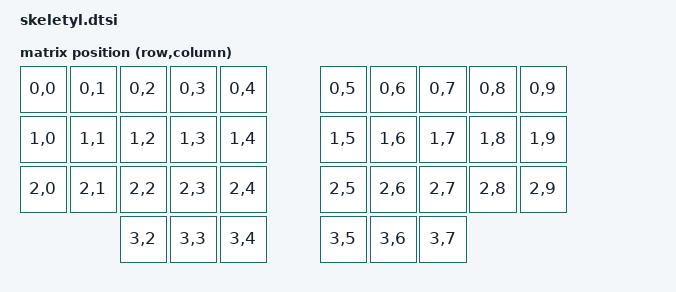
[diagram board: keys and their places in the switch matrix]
// This file was generated from a template. Edit it to match your keyboard.
// See https://zmk.dev/docs/development/hardware-integration/new-shield for more
// instructions.

#include <dt-bindings/zmk/matrix_transform.h>

#include "skeletyl-layouts.dtsi"

/ {
    chosen {
        zmk,kscan = &kscan
        zmk,physical-layout = &default_layout;
    };

    kscan: kscan {
        // Set this to "col2row" or "row2col" to match the hardware. If using
        // "row2col", change the col-gpios in the _left.overlay and _right.overlay
        // files to (GPIO_ACTIVE_HIGH | GPIO_PULL_DOWN) and the row-gpios here to
        // GPIO_ACTIVE_HIGH.
        diode-direction = "col2row";
        wakeup-source;
    };

    default_transform: default_transform {
        // See https://zmk.dev/docs/development/hardware-integration/new-shield#matrix-transform
        // for how to configure this
        compatible = "zmk,matrix-transform";
        columns = <10>;
        rows = <4>;

        map = <
            RC(0, 0) RC(0, 1) RC(0, 2) RC(0, 3) RC(0, 4)    RC(0, 5) RC(0, 6) RC(0, 7) RC(0, 8) RC(0, 9)
            RC(1, 0) RC(1, 1) RC(1, 2) RC(1, 3) RC(1, 4)    RC(1, 5) RC(1, 6) RC(1, 7) RC(1, 8) RC(1, 9)
            RC(2, 0) RC(2, 1) RC(2, 2) RC(2, 3) RC(2, 4)    RC(2, 5) RC(2, 6) RC(2, 7) RC(2, 8) RC(2, 9)
                              RC(3, 2) RC(3, 3) RC(3, 4)    RC(3, 5) RC(3, 6) RC(3, 7)
        >;
    };
};
